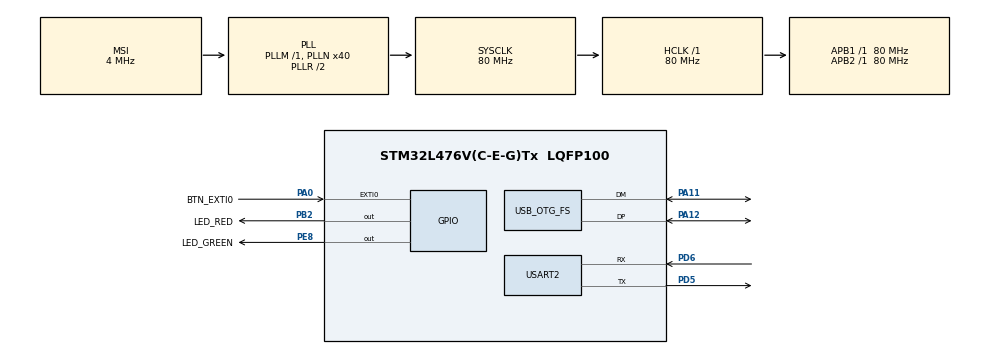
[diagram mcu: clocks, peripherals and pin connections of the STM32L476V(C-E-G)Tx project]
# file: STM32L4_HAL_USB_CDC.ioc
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Mcu.Family=STM32L4
Mcu.Name=STM32L476V(C-E-G)Tx
Mcu.Package=LQFP100
NVIC.EXTI0_IRQn=true\:0\:0\:false\:false\:true\:true\:true\:true
NVIC.OTG_FS_IRQn=true\:0\:0\:false\:false\:true\:false\:true\:true
NVIC.PriorityGroup=NVIC_PRIORITYGROUP_4
PA0.GPIO_Label=BTN_EXTI0
PA0.Signal=GPXTI0
PA11.Mode=Device_Only
PA11.Signal=USB_OTG_FS_DM
PA12.Mode=Device_Only
PA12.Signal=USB_OTG_FS_DP
PA13\ (JTMS-SWDIO).Mode=Serial_Wire
PA13\ (JTMS-SWDIO).Signal=SYS_JTMS-SWDIO
PA14\ (JTCK-SWCLK).Mode=Serial_Wire
PA14\ (JTCK-SWCLK).Signal=SYS_JTCK-SWCLK
PB2.GPIO_Label=LED_RED
PB2.Signal=GPIO_Output
PC14-OSC32_IN\ (PC14).Mode=LSE-External-Oscillator
PC14-OSC32_IN\ (PC14).Signal=RCC_OSC32_IN
PC15-OSC32_OUT\ (PC15).Mode=LSE-External-Oscillator
PC15-OSC32_OUT\ (PC15).Signal=RCC_OSC32_OUT
PD5.Mode=Asynchronous
PD5.Signal=USART2_TX
PD6.Mode=Asynchronous
PD6.Signal=USART2_RX
PE8.GPIO_Label=LED_GREEN
PE8.Signal=GPIO_Output
ProjectManager.HeapSize=0x200
ProjectManager.StackSize=0x400
ProjectManager.TargetToolchain=STM32CubeIDE
RCC.ADCFreq_Value=48000000
RCC.AHBFreq_Value=80000000
RCC.APB1Freq_Value=80000000
RCC.APB1TimFreq_Value=80000000
RCC.APB2Freq_Value=80000000
RCC.APB2TimFreq_Value=80000000
RCC.CortexFreq_Value=80000000
RCC.HCLKFreq_Value=80000000
RCC.HSE_VALUE=8000000
RCC.HSI_VALUE=16000000
RCC.MSI_VALUE=4000000
RCC.PLLN=40
RCC.PLLSAI1N=24
RCC.SYSCLKFreq_VALUE=80000000
RCC.SYSCLKSource=RCC_SYSCLKSOURCE_PLLCLK
RCC.USBFreq_Value=48000000
RCC.VCOOutputFreq_Value=160000000
USART2.VirtualMode-Asynchronous=VM_ASYNC
USB_DEVICE.CLASS_NAME_FS=CDC
USB_DEVICE.VirtualMode=Cdc
USB_DEVICE.VirtualModeFS=Cdc_FS
USB_OTG_FS.VirtualMode=Device_Only
VP_USB_DEVICE_VS_USB_DEVICE_CDC_FS.Mode=CDC_FS
board=STM32L476G-DISCO

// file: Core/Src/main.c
/* USER CODE BEGIN Header */
/**
 ******************************************************************************
 * @file           : main.c
 * @brief          : Main program body
 ******************************************************************************
 * @attention
 *
 * Copyright (c) 2023 STMicroelectronics.
 * All rights reserved.
 *
 * This software is licensed under terms that can be found in the LICENSE file
 * in the root directory of this software component.
 * If no LICENSE file comes with this software, it is provided AS-IS.
 *
 ******************************************************************************
 */
/* USER CODE END Header */
#include "main.h"
#include "usart.h"
#include "usb_device.h"
#include "gpio.h"

/* USER CODE BEGIN Includes */

#include <string.h>
#include "usbd_cdc_if.h"

/* USER CODE END Includes */

void SystemClock_Config(void);

/* USER CODE BEGIN 0 */
extern USBD_HandleTypeDef hUsbDeviceFS;
uint8_t UserRxBuffer[APP_RX_DATA_SIZE];
uint8_t UserTxBuffer[APP_TX_DATA_SIZE] = "Hello, STM32L4!\r\n";

/* USER CODE END 0 */

int main(void)
{

  /* MCU Configuration--------------------------------------------------------*/

  /* Reset of all peripherals, Initializes the Flash interface and the Systick. */
  HAL_Init();

  /* Configure the system clock */
  SystemClock_Config();

  /* Initialize all configured peripherals */
  MX_GPIO_Init();
  MX_USART2_UART_Init();
  MX_USB_DEVICE_Init();

  /* Infinite loop */
  while (1)
  {

    /* USER CODE BEGIN 3 */

    if(UserRxBuffer[0] == 'A')
    {
      HAL_GPIO_TogglePin(LED_GREEN_GPIO_Port, LED_GREEN_Pin);
    }
    else if(UserRxBuffer[0] == 'B')
    {
      HAL_GPIO_TogglePin(LED_RED_GPIO_Port, LED_RED_Pin);
    }
    else if(UserRxBuffer[0] == 'C')
    {
      USBD_CDC_SetTxBuffer(&hUsbDeviceFS, UserTxBuffer, strlen((const char*)UserTxBuffer));
      USBD_CDC_TransmitPacket(&hUsbDeviceFS);
    }

    // clear buffer
    memset(UserRxBuffer, 0, sizeof(UserRxBuffer));
  }
  /* USER CODE END 3 */
}

void SystemClock_Config(void)
{
  RCC_OscInitTypeDef RCC_OscInitStruct = {0};
  RCC_ClkInitTypeDef RCC_ClkInitStruct = {0};

  /** Configure the main internal regulator output voltage
   */
  if (HAL_PWREx_ControlVoltageScaling(PWR_REGULATOR_VOLTAGE_SCALE1) != HAL_OK)
  {
    Error_Handler();
  }

  /** Configure LSE Drive Capability
   */
  HAL_PWR_EnableBkUpAccess();
  __HAL_RCC_LSEDRIVE_CONFIG(RCC_LSEDRIVE_LOW);

  /** Initializes the RCC Oscillators according to the specified parameters
   * in the RCC_OscInitTypeDef structure.
   */
  RCC_OscInitStruct.OscillatorType = RCC_OSCILLATORTYPE_LSE|RCC_OSCILLATORTYPE_MSI;
  RCC_OscInitStruct.LSEState = RCC_LSE_ON;
  RCC_OscInitStruct.MSIState = RCC_MSI_ON;
  RCC_OscInitStruct.MSICalibrationValue = 0;
  RCC_OscInitStruct.MSIClockRange = RCC_MSIRANGE_6;
  RCC_OscInitStruct.PLL.PLLState = RCC_PLL_ON;
  RCC_OscInitStruct.PLL.PLLSource = RCC_PLLSOURCE_MSI;
  RCC_OscInitStruct.PLL.PLLM = 1;
  RCC_OscInitStruct.PLL.PLLN = 40;
  RCC_OscInitStruct.PLL.PLLP = RCC_PLLP_DIV7;
  RCC_OscInitStruct.PLL.PLLQ = RCC_PLLQ_DIV2;
  RCC_OscInitStruct.PLL.PLLR = RCC_PLLR_DIV2;
  if (HAL_RCC_OscConfig(&RCC_OscInitStruct) != HAL_OK)
  {
    Error_Handler();
  }

  /** Initializes the CPU, AHB and APB buses clocks
   */
  RCC_ClkInitStruct.ClockType = RCC_CLOCKTYPE_HCLK|RCC_CLOCKTYPE_SYSCLK
      |RCC_CLOCKTYPE_PCLK1|RCC_CLOCKTYPE_PCLK2;
  RCC_ClkInitStruct.SYSCLKSource = RCC_SYSCLKSOURCE_PLLCLK;
  RCC_ClkInitStruct.AHBCLKDivider = RCC_SYSCLK_DIV1;
  RCC_ClkInitStruct.APB1CLKDivider = RCC_HCLK_DIV1;
  RCC_ClkInitStruct.APB2CLKDivider = RCC_HCLK_DIV1;

  if (HAL_RCC_ClockConfig(&RCC_ClkInitStruct, FLASH_LATENCY_4) != HAL_OK)
  {
    Error_Handler();
  }

  /** Enable MSI Auto calibration
   */
  HAL_RCCEx_EnableMSIPLLMode();
}

void Error_Handler(void)
{
  __disable_irq();
  while (1)
  {
  }
}
